# STM32G554xx register map
File version: 1.0
Registers are 32-bit, read-write, reset 0x0 unless marked. A register's access mark holds for its fields unless they carry their own. Offsets are from the block's base; [hi:lo] are bit positions; lines under a group give offsets from that group; {n}, {i} and the like mark numbered series.

## ADC1 — Analog to Digital Converter (ADC)
Base 0x42020000
Same registers: ADC2 0x42020100
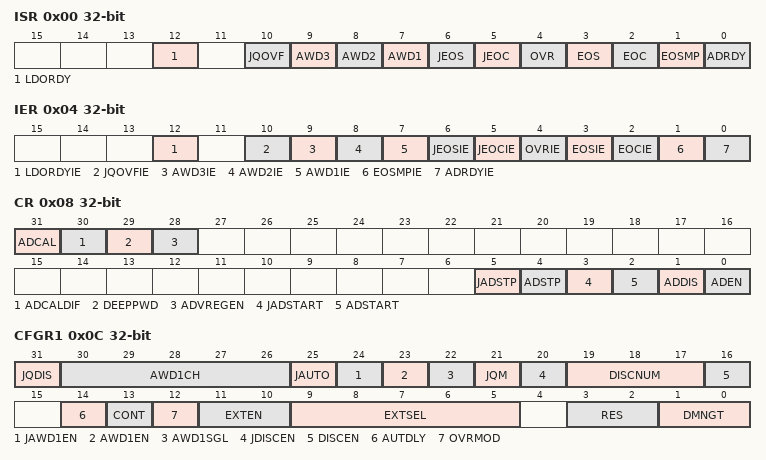
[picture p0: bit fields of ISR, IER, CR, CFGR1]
0x00 ISR — ADC interrupt and status register
  [12] LDORDY
  [10] JQOVF — Injected context queue overflow
  [9] AWD3 — Analog watchdog 3 flag
  [8] AWD2 — Analog watchdog 2 flag
  [7] AWD1 — Analog watchdog 1 flag
  [6] JEOS — Injected channel end of sequence flag
  [5] JEOC — Injected channel end of conversion flag
  [4] OVR — ADC overrun
  [3] EOS — End of regular sequence flag
  [2] EOC — End of conversion flag
  [1] EOSMP — End of sampling flag
  [0] ADRDY — ADC ready
0x04 IER — ADC interrupt enable register
  [12] LDORDYIE
  [10] JQOVFIE
  [9] AWD3IE — Analog watchdog 3 interrupt enable
  [8] AWD2IE — Analog watchdog 2 interrupt enable
  [7] AWD1IE — Analog watchdog 1 interrupt enable
  [6] JEOSIE
  [5] JEOCIE
  [4] OVRIE — Overrun interrupt enable
  [3] EOSIE
  [2] EOCIE
  [1] EOSMPIE
  [0] ADRDYIE — ADC ready interrupt enable
0x08 CR — ADC control register
  [31] ADCAL — ADC calibration
  [30] ADCALDIF — Differential mode for calibration
  [29] DEEPPWD — Deep-power-down enable
  [28] ADVREGEN — ADC internal voltage regulator enable
  [5] JADSTP — ADC stop of injected conversion command
  [4] ADSTP — ADC stop of regular conversion command
  [3] JADSTART — ADC start of injected conversion
  [2] ADSTART — ADC start of regular conversion
  [1] ADDIS — ADC disable command
  [0] ADEN — ADC enable control
0x0C CFGR1 — ADC configuration register
  [31] JQDIS — Injected queue disable
  [30:26] AWD1CH — Analog watchdog 1 channel selection
  [25] JAUTO — Automatic injected group conversion
  [24] JAWD1EN
  [23] AWD1EN
  [22] AWD1SGL
  [21] JQM — ADC_JSQR queue mode
  [20] JDISCEN — Discontinuous mode on injected channels
  [19:17] DISCNUM — Discontinuous mode channel count
  [16] DISCEN — Discontinuous mode for regular channels
  [14] AUTDLY — Delayed conversion mode
  [13] CONT
  [12] OVRMOD — Overrun mode
  [11:10] EXTEN
  [9:5] EXTSEL
  [3:2] RES — Data resolution
  [1:0] DMNGT — Data management configuration
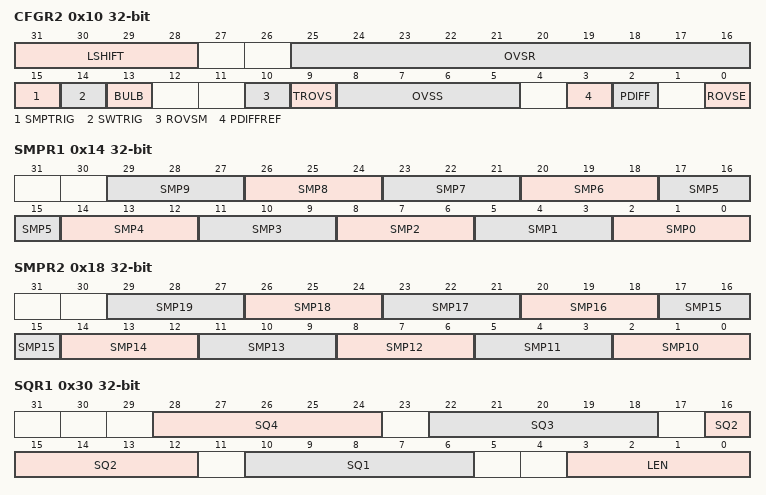
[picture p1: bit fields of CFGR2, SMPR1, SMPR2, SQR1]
0x10 CFGR2 — ADC configuration register 2
  [31:28] LSHIFT — Left shift factor
  [25:16] OVSR — Oversampling ratio
  [15] SMPTRIG — Sampling time control trigger mode
  [14] SWTRIG
  [13] BULB — Bulb sampling mode
  [10] ROVSM — Regular oversampling mode
  [9] TROVS — Triggered regular oversampling
  [8:5] OVSS — Oversampling shift
  [3] PDIFFREF
  [2] PDIFF — Pseudodifferential mode enable
  [0] ROVSE — Regular oversampling enable
0x14 SMPR1 — ADC sample time register 1
  [3n+2:3n] SMP{n} (n=0..9)
0x18 SMPR2 — ADC sample time register 2
  [3n-28:3n-30] SMP{n} (n=10..19)
0x1C PCSEL — ADC channel preselection register
  [19:0] PCSEL
0x30 SQR1 — ADC regular sequence register 1
  [28:24] SQ4 — 4th conversion in regular sequence
  [22:18] SQ3 — 3rd conversion in regular sequence
  [16:12] SQ2 — 2nd conversion in regular sequence
  [10:6] SQ1 — 1st conversion in regular sequence
  [3:0] LEN — Regular channel sequence length
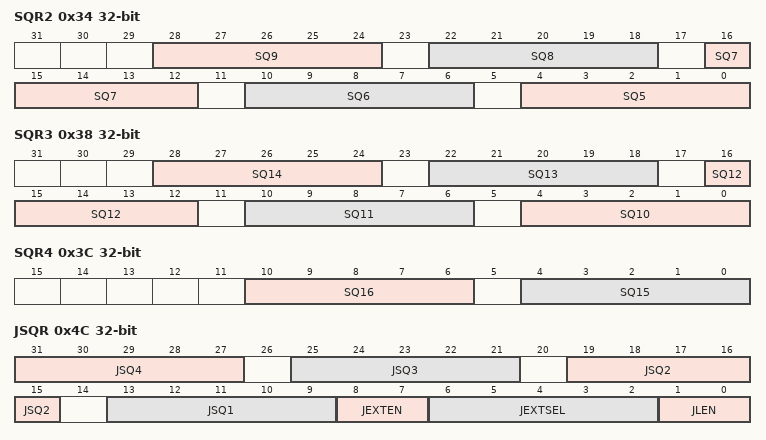
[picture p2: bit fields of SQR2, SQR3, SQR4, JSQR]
0x34 SQR2 — ADC regular sequence register 2
  [6n-26:6n-30] SQ{n} (n=5..9) — {n}th conversion in regular sequence
0x38 SQR3 — ADC regular sequence register 3
  [6n-56:6n-60] SQ{n} (n=10..14) — {n}th conversion in regular sequence
0x3C SQR4 — ADC regular sequence register 4
  [10:6] SQ16 — 16th conversion in regular sequence
  [4:0] SQ15 — 15th conversion in regular sequence
0x40 DR ro — ADC regular data register
  [31:0] RDATA — Regular data converted
0x4C JSQR — ADC injected sequence register
  [31:27] JSQ4 — 4th conversion in the injected sequence
  [25:21] JSQ3 — 3rd conversion in the injected sequence
  [19:15] JSQ2 — 2nd conversion in the injected sequence
  [13:9] JSQ1 — 1st conversion in the injected sequence
  [8:7] JEXTEN
  [6:2] JEXTSEL
  [1:0] JLEN — Injected channel sequence length
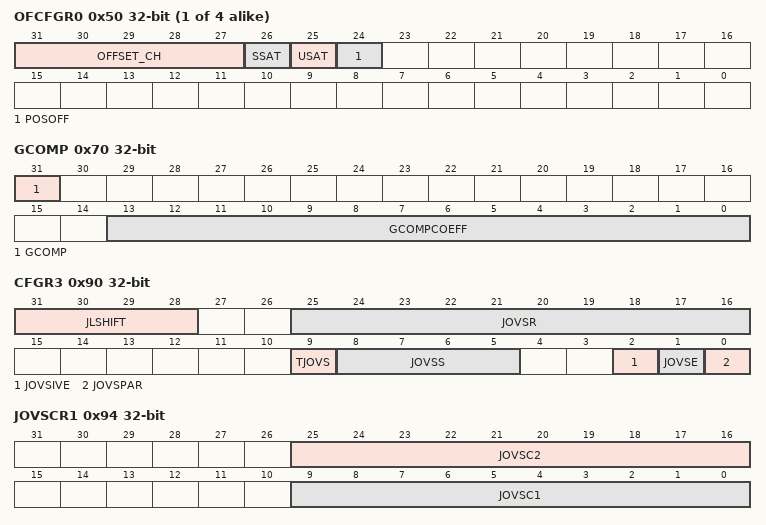
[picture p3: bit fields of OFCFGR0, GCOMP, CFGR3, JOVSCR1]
{0x50+4i} OFCFGR{i} (i=0..3) — ADC
  [31:27] OFFSET_CH — Channel selection for the data offset y
  [26] SSAT — Signed saturation enable
  [25] USAT — Unsigned saturation enable
  [24] POSOFF — Positive offset enable
{0x60+4i} OFR{i} (i=0..3) — ADC
  [21:0] OFFSET
0x70 GCOMP — ADC gain compensation register
  [31] GCOMP — Gain compensation mode
  [13:0] GCOMPCOEFF — Gain compensation coefficient
{0x70+4i} AWD{i}SR (i=1..3) — ADC analog watchdog {i} source channel register
  [19:0] AWDS_CH
{0x80+4i} JDR{i} ro (i=0..3) — ADC injected channel 1 data register
  [31:0] JDATA — Injected data
0x90 CFGR3 — ADC configuration register 3
  [31:28] JLSHIFT — Left shift factor
  [25:16] JOVSR — Injected channel oversampling ratio
  [9] TJOVS — Triggered injected channel oversampling
  [8:5] JOVSS — Injected channel oversampling shift
  [2] JOVSIVE
  [1] JOVSE — Injected oversampling enable
  [0] JOVSPAR — Parallel injected oversampling enable
0x94 JOVSCR1 ro — ADC injected oversampling counter register 1
  [25:16] JOVSC2, [9:0] JOVSC1
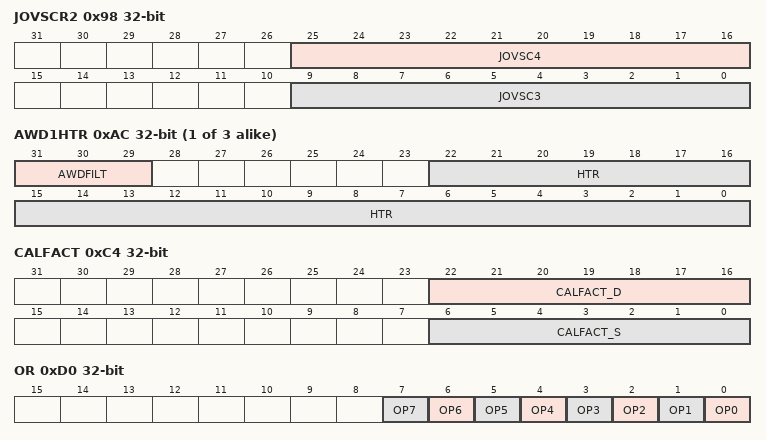
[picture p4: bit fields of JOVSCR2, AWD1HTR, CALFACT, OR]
0x98 JOVSCR2 ro — ADC injected oversampling counter register 2
  [25:16] JOVSC4, [9:0] JOVSC3
0xA0 AWD2CR — ADC analog watchdog 2 configuration register
  [19:0] AWDCH — Analog watchdog 2 channel selection
0xA4 AWD3CR — ADC analog watchdog 3 configuration register
  [19:0] AWDCH — Analog watchdog 3 channel selection
{0xA0+8i} AWD{i}LTR (i=1..3) — ADC analog watchdog {i} lower threshold register
  [22:0] LTR — Analog watchdog {i} lower threshold
{0xA4+8i} AWD{i}HTR (i=1..3) — ADC analog watchdog {i} higher threshold register
  [31:29] AWDFILT — Analog watchdog filtering parameter
  [22:0] HTR — Analog watchdog {i} higher threshold
0xC0 DIFSEL — ADC differential mode selection register
  [19:0] DIFSEL — Differential mode for channels 19 to 0
0xC4 CALFACT — ADC calibration factors
  [22:16] CALFACT_D, [6:0] CALFACT_S
0xD0 OR — ADC option register
  [n] OP{n} (n=0..7) — Option bit {n}

## ADC3 — Analog to Digital Converter (ADC)
Base 0x42020400
Registers as ADC1; these are added or differ:
0x300 CSR ro — ADC common status register
0x308 CCR — ADC common control register
0x30C CDR ro — ADC common regular data register for dual mode
0x310 CDR2 ro — ADC common regular data register for dual mode
